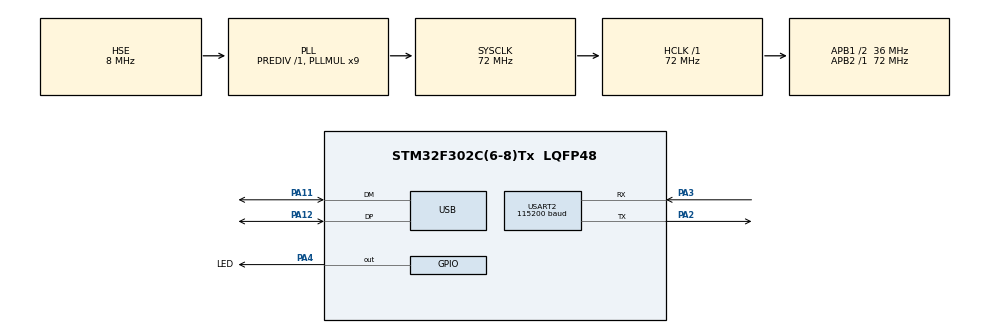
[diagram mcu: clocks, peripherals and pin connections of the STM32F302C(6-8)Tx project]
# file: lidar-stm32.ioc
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Dma.Request0=USART2_RX
Dma.USART2_RX.0.Direction=DMA_PERIPH_TO_MEMORY
Dma.USART2_RX.0.Instance=DMA1_Channel6
Dma.USART2_RX.0.MemDataAlignment=DMA_MDATAALIGN_BYTE
Dma.USART2_RX.0.MemInc=DMA_MINC_ENABLE
Dma.USART2_RX.0.Mode=DMA_NORMAL
Dma.USART2_RX.0.PeriphDataAlignment=DMA_PDATAALIGN_BYTE
Dma.USART2_RX.0.PeriphInc=DMA_PINC_DISABLE
Dma.USART2_RX.0.Priority=DMA_PRIORITY_LOW
Mcu.Family=STM32F3
Mcu.Name=STM32F302C(6-8)Tx
Mcu.Package=LQFP48
NVIC.DMA1_Channel6_IRQn=true\:0\:0\:false\:false\:true\:false\:true
NVIC.PriorityGroup=NVIC_PRIORITYGROUP_4
NVIC.USART2_IRQn=true\:0\:0\:false\:false\:true\:true\:true
PA11.Mode=Device
PA11.Signal=USB_DM
PA12.Mode=Device
PA12.Signal=USB_DP
PA2.Mode=Asynchronous
PA2.Signal=USART2_TX
PA3.Mode=Asynchronous
PA3.Signal=USART2_RX
PA4.GPIO_Label=LED
PA4.Signal=GPIO_Output
PF0-OSC_IN.Mode=HSE-External-Oscillator
PF0-OSC_IN.Signal=RCC_OSC_IN
PF1-OSC_OUT.Mode=HSE-External-Oscillator
PF1-OSC_OUT.Signal=RCC_OSC_OUT
ProjectManager.HeapSize=0x200
ProjectManager.StackSize=0x400
ProjectManager.TargetToolchain=Makefile
RCC.AHBFreq_Value=72000000
RCC.APB1CLKDivider=RCC_HCLK_DIV2
RCC.APB1Freq_Value=36000000
RCC.APB1TimFreq_Value=72000000
RCC.APB2Freq_Value=72000000
RCC.APB2TimFreq_Value=72000000
RCC.CortexFreq_Value=72000000
RCC.HCLKFreq_Value=72000000
RCC.HSE_VALUE=8000000
RCC.HSI_VALUE=8000000
RCC.LSE_VALUE=32768
RCC.PLLMUL=RCC_PLL_MUL9
RCC.PRESCALERUSB=RCC_USBCLKSOURCE_PLL_DIV1_5
RCC.SYSCLKFreq_VALUE=72000000
RCC.SYSCLKSourceVirtual=RCC_SYSCLKSOURCE_PLLCLK
RCC.USBFreq_Value=48000000
RCC.Usart1ClockSelection=RCC_USART1CLKSOURCE_SYSCLK
USART2.BaudRate=115200
USART2.RxPinLevelInvertParam=ADVFEATURE_RXINV_DISABLE
USART2.VirtualMode-Asynchronous=VM_ASYNC
board=custom

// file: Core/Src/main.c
/* USER CODE BEGIN Header */
/**
  ******************************************************************************
  * @file           : main.c
  * @brief          : Main program body
  ******************************************************************************
  * @attention
  *
  * <h2><center>&copy; Copyright (c) 2021 STMicroelectronics.
  * All rights reserved.</center></h2>
  *
  * This software component is licensed by ST under Ultimate Liberty license
  * SLA0044, the "License"; You may not use this file except in compliance with
  * the License. You may obtain a copy of the License at:
  *                             www.st.com/SLA0044
  *
  ******************************************************************************
  */
/* USER CODE END Header */
#include "main.h"
#include "dma.h"
#include "usart.h"
#include "gpio.h"
#include "usbd_cdc_if.h"
#include "usb_device.h"

/* USER CODE BEGIN PTD */
LD06 lidar;
uint8_t buffer = 0;
uint8_t TXmsg = 1;
/* USER CODE END PTD */

void SystemClock_Config(void);
/* USER CODE BEGIN PFP */

int _write(int fd, unsigned char *ptr, int len)
{
	if (CDC_Transmit_FS(ptr,len) != HAL_OK)
		return 0;

	return len;
}

/* USER CODE END PFP */

int main(void)
{

  /* MCU Configuration--------------------------------------------------------*/

  /* Reset of all peripherals, Initializes the Flash interface and the Systick. */
  HAL_Init();

  /* Configure the system clock */
  SystemClock_Config();

  /* Initialize all configured peripherals */
  MX_GPIO_Init();
  MX_DMA_Init();
  MX_USB_DEVICE_Init();
  MX_USART2_UART_Init();
  /* USER CODE BEGIN 2 */
  HAL_UART_Receive_DMA(&huart2,&buffer,sizeof(buffer));
  //UART_Start_Receive_DMA(&huart2,&buffer,sizeof(buffer));
  printf("Config ok\r\n");
  //HAL_GPIO_TogglePin(LED_GPIO_Port,LED_Pin);

  /* USER CODE END 2 */

  /* Infinite loop */
  /* USER CODE BEGIN WHILE */
  while (1)
  {
    //printf("Config ok\r\n");
    //printf("cc\n\r");

      //HAL_GPIO_TogglePin(LED_GPIO_Port,LED_Pin);
     printf("datalength= %li , radarspeed= %f , start angle = %f , stop angle= %f , distance= %f  \r\n ",lidar.dataLength,lidar.radarSpeed,lidar.startAngle,lidar.endAngle,lidar.distance);
    /* USER CODE END WHILE */

  }
}

void SystemClock_Config(void)
{
  RCC_OscInitTypeDef RCC_OscInitStruct = {0};
  RCC_ClkInitTypeDef RCC_ClkInitStruct = {0};
  RCC_PeriphCLKInitTypeDef PeriphClkInit = {0};

  /** Initializes the RCC Oscillators according to the specified parameters
  * in the RCC_OscInitTypeDef structure.
  */
  RCC_OscInitStruct.OscillatorType = RCC_OSCILLATORTYPE_HSE;
  RCC_OscInitStruct.HSEState = RCC_HSE_ON;
  RCC_OscInitStruct.HSEPredivValue = RCC_HSE_PREDIV_DIV1;
  RCC_OscInitStruct.HSIState = RCC_HSI_ON;
  RCC_OscInitStruct.PLL.PLLState = RCC_PLL_ON;
  RCC_OscInitStruct.PLL.PLLSource = RCC_PLLSOURCE_HSE;
  RCC_OscInitStruct.PLL.PLLMUL = RCC_PLL_MUL9;
  if (HAL_RCC_OscConfig(&RCC_OscInitStruct) != HAL_OK)
  {
    Error_Handler();
  }
  /** Initializes the CPU, AHB and APB buses clocks
  */
  RCC_ClkInitStruct.ClockType = RCC_CLOCKTYPE_HCLK|RCC_CLOCKTYPE_SYSCLK
                              |RCC_CLOCKTYPE_PCLK1|RCC_CLOCKTYPE_PCLK2;
  RCC_ClkInitStruct.SYSCLKSource = RCC_SYSCLKSOURCE_PLLCLK;
  RCC_ClkInitStruct.AHBCLKDivider = RCC_SYSCLK_DIV1;
  RCC_ClkInitStruct.APB1CLKDivider = RCC_HCLK_DIV2;
  RCC_ClkInitStruct.APB2CLKDivider = RCC_HCLK_DIV1;

  if (HAL_RCC_ClockConfig(&RCC_ClkInitStruct, FLASH_LATENCY_2) != HAL_OK)
  {
    Error_Handler();
  }
  PeriphClkInit.PeriphClockSelection = RCC_PERIPHCLK_USB;
  PeriphClkInit.USBClockSelection = RCC_USBCLKSOURCE_PLL_DIV1_5;
  if (HAL_RCCEx_PeriphCLKConfig(&PeriphClkInit) != HAL_OK)
  {
    Error_Handler();
  }
}

/* USER CODE BEGIN 4 */
void HAL_UART_RxCpltCallback(UART_HandleTypeDef *huart)
{
  HAL_GPIO_TogglePin(LED_GPIO_Port,LED_Pin);
  //printf("cc\n\r");
  readLidarData(&huart2,&lidar,&buffer);
  //printf("distance=%f , angle=%f \n\r",lidar.distance,lidar.endAngle);
  HAL_UART_Receive_DMA(&huart2,&buffer,8);
}
/* USER CODE END 4 */

void Error_Handler(void)
{
  /* USER CODE BEGIN Error_Handler_Debug */
  //printf("error\n\r");
  __disable_irq();
  while (1)
  {
  }
  /* USER CODE END Error_Handler_Debug */
}

/************************ (C) COPYRIGHT STMicroelectronics *****END OF FILE****/
